# MS32Cxxx_DFP register map
Vendor: MS; Series: MS32C; File version: 1.0.0
CPU: CM0+ r0p1, little endian, no MPU, no FPU, 4 interrupt priority bits
Registers are 32-bit, read-write, reset 0x0 unless marked. A register's access mark holds for its fields unless they carry their own. Offsets are from the block's base; [hi:lo] are bit positions; {n}, {i} and the like mark numbered series.

## GPIOA — General-purpose I/Os
Base 0x50000000
Same registers: GPIOB 0x50000400
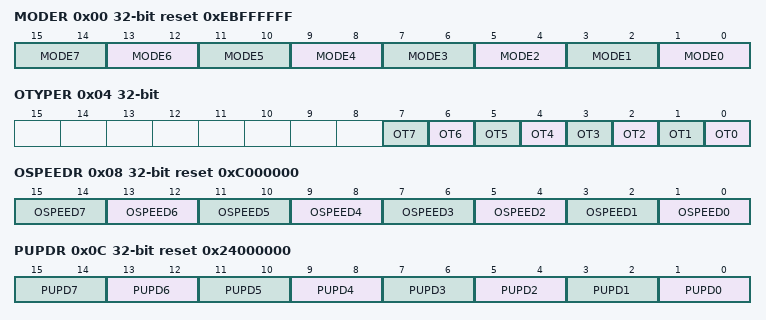
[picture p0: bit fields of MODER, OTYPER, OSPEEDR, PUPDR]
0x00 MODER reset 0xEBFFFFFF — GPIO port mode register
  [2n+1:2n] MODE{n} (n=0..7) — Port x configuration bits (y = 0..15)
0x04 OTYPER — GPIO port output type register
  [n] OT{n} (n=0..7) — Port x configuration bits (y = 0..15)
0x08 OSPEEDR reset 0xC000000 — GPIO port output speed register
  [2n+1:2n] OSPEED{n} (n=0..7) — Port x configuration bits (y = 0..15)
0x0C PUPDR reset 0x24000000 — GPIO port pull-up/pull-down register
  [2n+1:2n] PUPD{n} (n=0..7) — Port x configuration bits (y = 0..15)
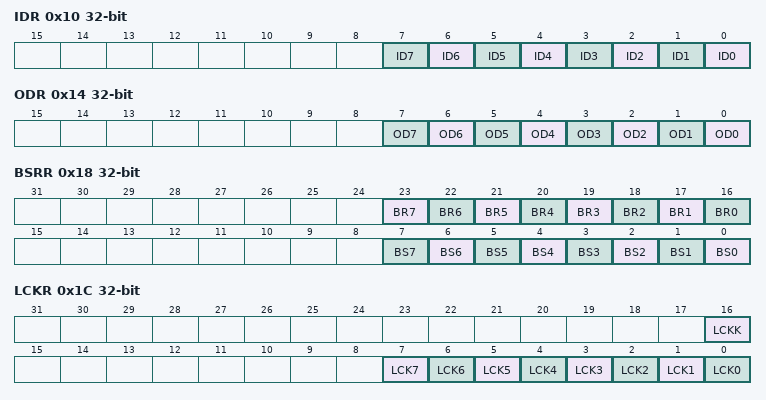
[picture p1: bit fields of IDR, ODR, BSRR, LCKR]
0x10 IDR ro — GPIO port input data register
  [n] ID{n} (n=0..7) — Port input data (y = 0..15)
0x14 ODR — GPIO port output data register
  [n] OD{n} (n=0..7) — Port output data (y = 0..15)
0x18 BSRR wo — GPIO port bit set/reset register
  [n+16] BR{n} (n=1..7) — Port x reset bit y (y = 0..15)
  [16] BR0 — Port x set bit y (y= 0..15)
  [n] BS{n} (n=0..7) — Port x set bit y (y= 0..15)
0x1C LCKR — GPIO port configuration lock register
  [16] LCKK — Port x lock bit y (y= 0..15)
  [n] LCK{n} (n=0..7) — Port x lock bit y (y= 0..15)
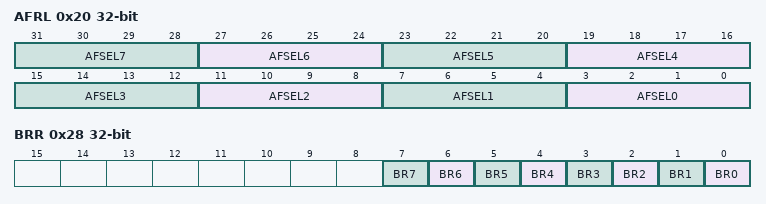
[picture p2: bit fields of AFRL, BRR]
0x20 AFRL — GPIO alternate function low register
  [4n+3:4n] AFSEL{n} (n=0..7) — Alternate function selection for port x bit y (y = 0..7)
0x28 BRR wo — port bit reset register
  [n] BR{n} (n=0..7) — Port Reset bit

## GPIOC — General-purpose I/Os
Base 0x50000800
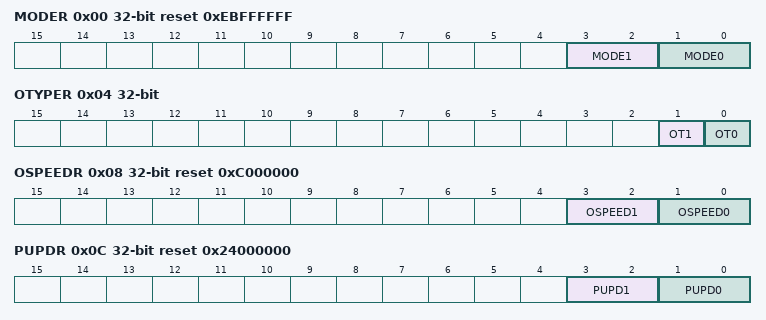
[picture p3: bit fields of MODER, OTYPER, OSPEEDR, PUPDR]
0x00 MODER reset 0xEBFFFFFF — GPIO port mode register
  [3:2] MODE1 — Port x configuration bits (y = 0..15)
  [1:0] MODE0 — Port x configuration bits (y = 0..15)
0x04 OTYPER — GPIO port output type register
  [1] OT1 — Port x configuration bits (y = 0..15)
  [0] OT0 — Port x configuration bits (y = 0..15)
0x08 OSPEEDR reset 0xC000000 — GPIO port output speed register
  [3:2] OSPEED1 — Port x configuration bits (y = 0..15)
  [1:0] OSPEED0 — Port x configuration bits (y = 0..15)
0x0C PUPDR reset 0x24000000 — GPIO port pull-up/pull-down register
  [3:2] PUPD1 — Port x configuration bits (y = 0..15)
  [1:0] PUPD0 — Port x configuration bits (y = 0..15)
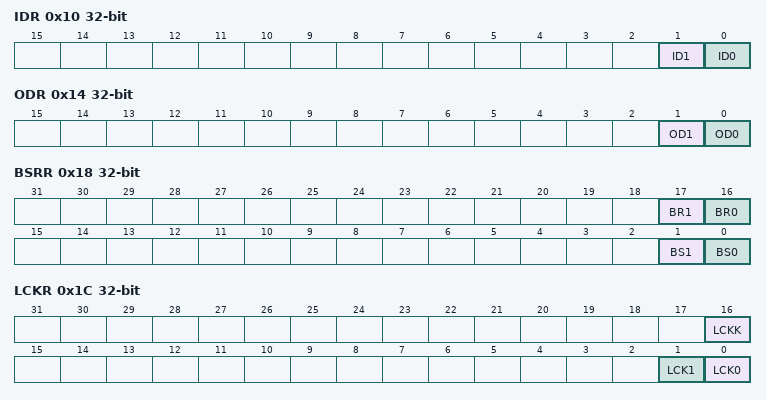
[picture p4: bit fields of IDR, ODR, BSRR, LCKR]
0x10 IDR ro — GPIO port input data register
  [1] ID1 — Port input data (y = 0..15)
  [0] ID0 — Port input data (y = 0..15)
0x14 ODR — GPIO port output data register
  [1] OD1 — Port output data (y = 0..15)
  [0] OD0 — Port output data (y = 0..15)
0x18 BSRR wo — GPIO port bit set/reset register
  [17] BR1 — Port x reset bit y (y = 0..15)
  [16] BR0 — Port x set bit y (y= 0..15)
  [1] BS1 — Port x set bit y (y= 0..15)
  [0] BS0 — Port x set bit y (y= 0..15)
0x1C LCKR — GPIO port configuration lock register
  [16] LCKK — Port x lock bit y (y= 0..15)
  [1] LCK1 — Port x lock bit y (y= 0..15)
  [0] LCK0 — Port x lock bit y (y= 0..15)
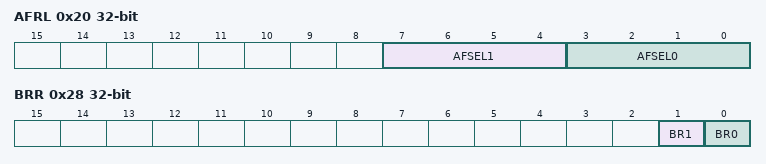
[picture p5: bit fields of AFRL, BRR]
0x20 AFRL — GPIO alternate function low register
  [7:4] AFSEL1 — Alternate function selection for port x bit y (y = 0..7)
  [3:0] AFSEL0 — Alternate function selection for port x bit y (y = 0..7)
0x28 BRR wo — port bit reset register
  [1] BR1 — Port Reset bit
  [0] BR0 — Port Reset bit

## EXTI — External interrupt/event controller
Base 0x40021800
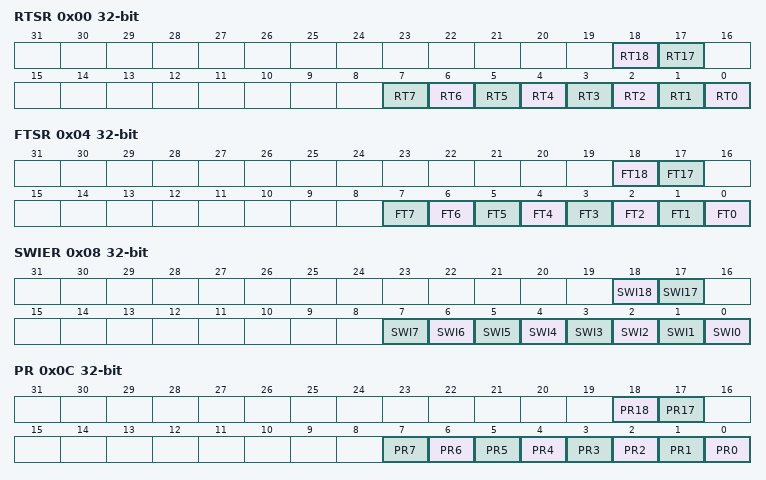
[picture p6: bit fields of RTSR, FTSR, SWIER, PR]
0x00 RTSR — EXTI rising trigger selection register
  [18] RT18 — Rising trigger event configuration bit of Configurable Event input
  [17] RT17 — Rising trigger event configuration bit of Configurable Event input
  [n] RT{n} (n=0..7) — Rising trigger event configuration bit of Configurable Event input
0x04 FTSR — EXTI falling trigger selection register
  [18] FT18 — Falling trigger event configuration bit of Configurable Event input
  [17] FT17 — Falling trigger event configuration bit of Configurable Event input
  [n] FT{n} (n=0..7) — Falling trigger event configuration bit of Configurable Event input
0x08 SWIER — EXTI software interrupt event register
  [18] SWI18 — Rising trigger event configuration bit of Configurable Event input
  [17] SWI17 — Rising trigger event configuration bit of Configurable Event input
  [n] SWI{n} (n=0..7) — Rising trigger event configuration bit of Configurable Event input
0x0C PR — EXTI pending register
  [18] PR18 — configurable event inputs x rising edge Pending bit.
  [17] PR17 — configurable event inputs x rising edge Pending bit.
  [n] PR{n} (n=0..7) — configurable event inputs x rising edge Pending bit.
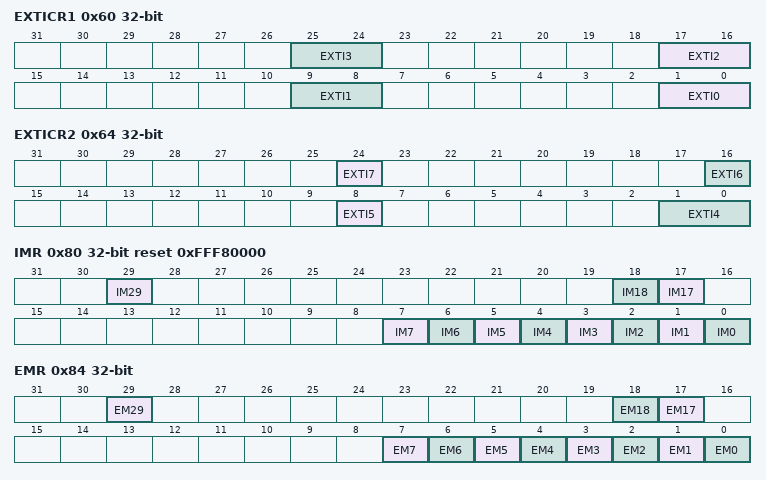
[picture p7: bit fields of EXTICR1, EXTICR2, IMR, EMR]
0x60 EXTICR1 — EXTI external interrupt selection register
  [8n+1:8n] EXTI{n} (n=0..3) — GPIO port selection
0x64 EXTICR2 — EXTI external interrupt selection register
  [24] EXTI7 — GPIO port selection
  [16] EXTI6 — GPIO port selection
  [8] EXTI5 — GPIO port selection
  [1:0] EXTI4 — GPIO port selection
0x80 IMR reset 0xFFF80000 — EXTI CPU wakeup with interrupt mask register
  [29] IM29 — CPU wakeup with interrupt mask on event input
  [18] IM18 — CPU wakeup with interrupt mask on event input
  [17] IM17 — CPU wakeup with interrupt mask on event input
  [n] IM{n} (n=0..7) — CPU wakeup with interrupt mask on event input
0x84 EMR — EXTI CPU wakeup with event mask register
  [29] EM29 — CPU wakeup with event mask on event input
  [18] EM18 — CPU wakeup with event mask on event input
  [17] EM17 — CPU wakeup with event mask on event input
  [n] EM{n} (n=0..7) — CPU wakeup with event mask on event input
